# HDSC_HC32M120F6TB register map
Vendor: HDSC Co.,Ltd.; Series: ARMCM0P; File version: 1.0
CPU: CM0P r0p1, little endian, no MPU, no FPU, 4 interrupt priority bits
Registers are 32-bit, read-write, reset 0x0 unless marked. A register's access mark holds for its fields unless they carry their own. Offsets are from the block's base; [hi:lo] are bit positions; {n}, {i} and the like mark numbered series; 'fields as' and 'values as' point back to an identical list.

## PWC
Base 0x40014000
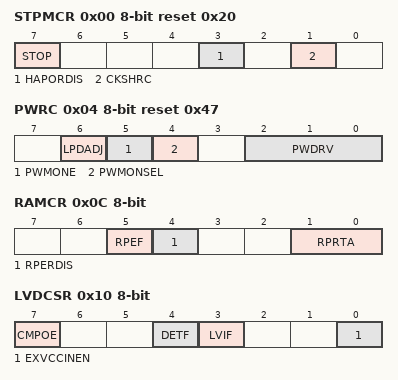
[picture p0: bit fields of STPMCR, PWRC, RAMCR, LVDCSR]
0x00 STPMCR 8-bit reset 0x20
  [7] STOP, [3] HAPORDIS, [1] CKSHRC
0x04 PWRC 8-bit reset 0x47
  [6] LPDADJ, [5] PWMONE, [4] PWMONSEL, [2:0] PWDRV
0x0C RAMCR 8-bit
  [5] RPEF, [4] RPERDIS, [1:0] RPRTA
0x10 LVDCSR 8-bit
  [7] CMPOE, [4] DETF, [3] LVIF ro, [0] EXVCCINEN
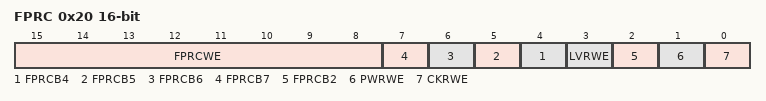
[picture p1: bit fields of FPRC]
0x20 FPRC 16-bit
  [15:8] FPRCWE wo, [n] FPRCB{n} (n=4..7), [3] LVRWE, [2] FPRCB2, [1] PWRWE, [0] CKRWE
0x40 DBGC 8-bit
  [0] DBGEN

## RMU
Base 0x40014100
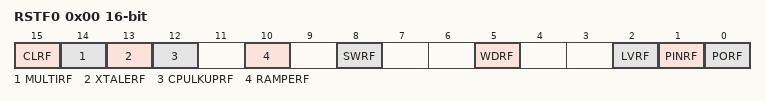
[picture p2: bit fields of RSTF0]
0x00 RSTF0 16-bit
  [15] CLRF, [14] MULTIRF, [13] XTALERF, [12] CPULKUPRF, [10] RAMPERF, [8] SWRF, [5] WDRF, [2] LVRF, [1] PINRF, [0] PORF

## SPI
Base 0x40003800
0x00 DR
  [15:0] SPD
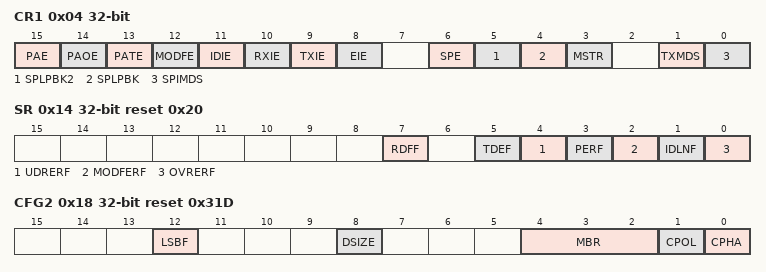
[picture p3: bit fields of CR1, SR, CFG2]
0x04 CR1
  [15] PAE, [14] PAOE, [13] PATE, [12] MODFE, [11] IDIE, [10] RXIE, [9] TXIE, [8] EIE, [6] SPE, [5] SPLPBK2, [4] SPLPBK, [3] MSTR, [1] TXMDS, [0] SPIMDS
0x0C CFG1 reset 0x10
  [8] SS0PV
0x14 SR reset 0x20
  [7] RDFF, [5] TDEF, [4] UDRERF, [3] PERF, [2] MODFERF, [1] IDLNF ro, [0] OVRERF
0x18 CFG2 reset 0x31D (reset mask 0x11F)
  [12] LSBF, [8] DSIZE, [4:2] MBR, [1] CPOL, [0] CPHA

## SWDT
Base 0x4000CC00
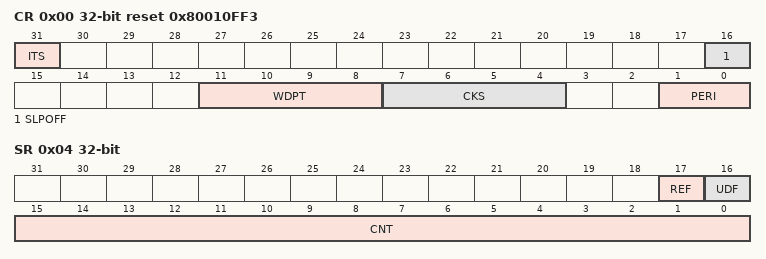
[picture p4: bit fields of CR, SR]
0x00 CR reset 0x80010FF3
  [31] ITS, [16] SLPOFF, [11:8] WDPT, [7:4] CKS, [1:0] PERI
0x04 SR ro
  [17] REF rw, [16] UDF rw, [15:0] CNT
0x08 RR ro
  [15:0] RF

## TMR0
Base 0x40005800
0x00 CNTAR
  [15:0] CNTA
0x08 CMPAR reset 0xFFFF
  [15:0] CMPA
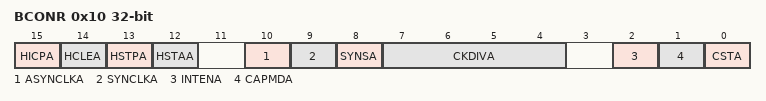
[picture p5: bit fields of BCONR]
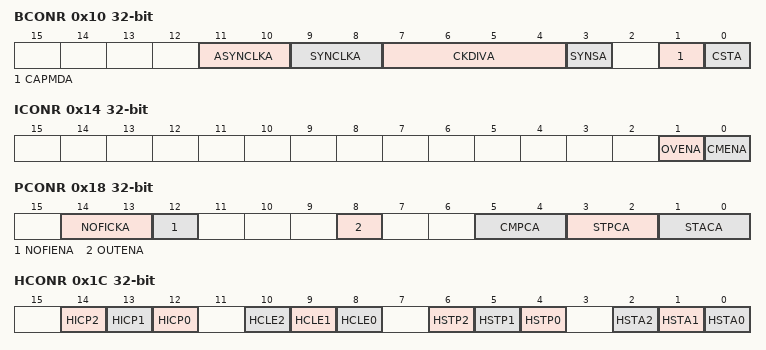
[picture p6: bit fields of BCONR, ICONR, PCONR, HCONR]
0x10 BCONR
  [15] HICPA, [14] HCLEA, [13] HSTPA, [12] HSTAA, [10] ASYNCLKA, [9] SYNCLKA, [8] SYNSA, [7:4] CKDIVA, [2] INTENA, [1] CAPMDA, [0] CSTA
0x14 STFLR
  [0] CMFA

## TMR2
Base 0x40006000
0x00 CNTAR
  [15:0] CNTA
0x08 CMPAR reset 0xFFFF
  [15:0] CMPA
0x10 BCONR
  [11:10] ASYNCLKA, [9:8] SYNCLKA, [7:4] CKDIVA, [3] SYNSA, [1] CAPMDA, [0] CSTA
0x14 ICONR
  [1] OVENA, [0] CMENA
0x18 PCONR
  [14:13] NOFICKA, [12] NOFIENA, [8] OUTENA, [5:4] CMPCA, [3:2] STPCA, [1:0] STACA
0x1C HCONR
  [14] HICP2, [13] HICP1, [12] HICP0, [10] HCLE2, [9] HCLE1, [8] HCLE0, [6] HSTP2, [5] HSTP1, [4] HSTP0, [2] HSTA2, [1] HSTA1, [0] HSTA0
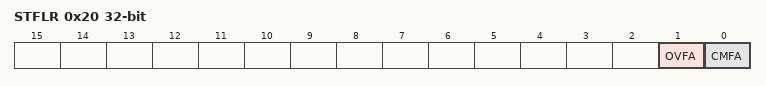
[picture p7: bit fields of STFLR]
0x20 STFLR
  [1] OVFA, [0] CMFA

## TMR4
Base 0x40006800
0x02 OCCRUH 16-bit
0x06 OCCRUL 16-bit
0x0A OCCRVH 16-bit
0x0E OCCRVL 16-bit
0x12 OCCRWH 16-bit
0x16 OCCRWL 16-bit
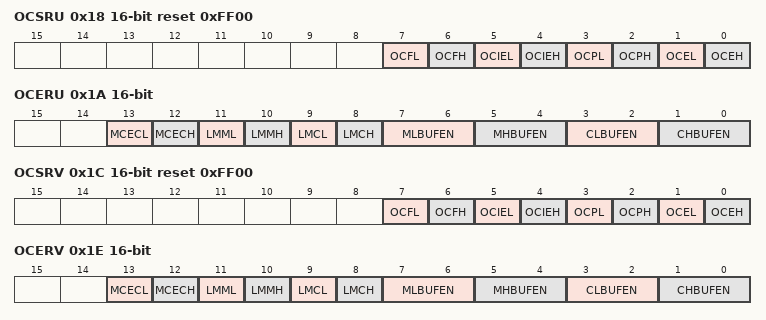
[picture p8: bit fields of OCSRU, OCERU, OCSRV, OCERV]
0x18 OCSRU 16-bit reset 0xFF00
  [7] OCFL, [6] OCFH, [5] OCIEL, [4] OCIEH, [3] OCPL, [2] OCPH, [1] OCEL, [0] OCEH
0x1A OCERU 16-bit
  [13] MCECL, [12] MCECH, [11] LMML, [10] LMMH, [9] LMCL, [8] LMCH, [7:6] MLBUFEN, [5:4] MHBUFEN, [3:2] CLBUFEN, [1:0] CHBUFEN
0x1C OCSRV 16-bit reset 0xFF00
  fields as OCSRU
0x1E OCERV 16-bit
  fields as OCERU
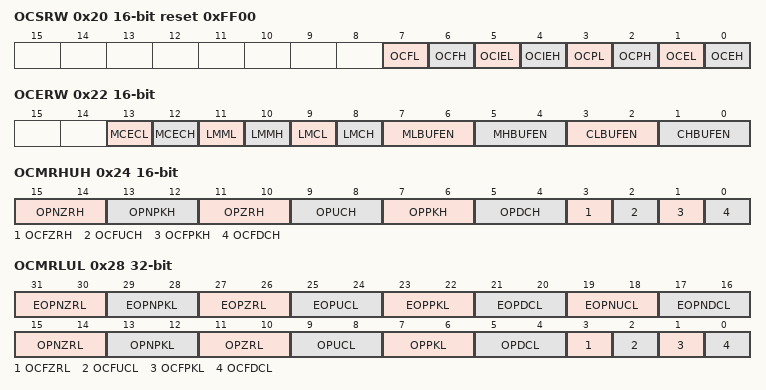
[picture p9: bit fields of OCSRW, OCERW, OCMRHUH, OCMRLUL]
0x20 OCSRW 16-bit reset 0xFF00
  fields as OCSRU
0x22 OCERW 16-bit
  fields as OCERU
0x24 OCMRHUH 16-bit
  [15:14] OPNZRH, [13:12] OPNPKH, [11:10] OPZRH, [9:8] OPUCH, [7:6] OPPKH, [5:4] OPDCH, [3] OCFZRH, [2] OCFUCH, [1] OCFPKH, [0] OCFDCH
0x28 OCMRLUL
  [31:30] EOPNZRL, [29:28] EOPNPKL, [27:26] EOPZRL, [25:24] EOPUCL, [23:22] EOPPKL, [21:20] EOPDCL, [19:18] EOPNUCL, [17:16] EOPNDCL, [15:14] OPNZRL, [13:12] OPNPKL, [11:10] OPZRL, [9:8] OPUCL, [7:6] OPPKL, [5:4] OPDCL, [3] OCFZRL, [2] OCFUCL, [1] OCFPKL, [0] OCFDCL
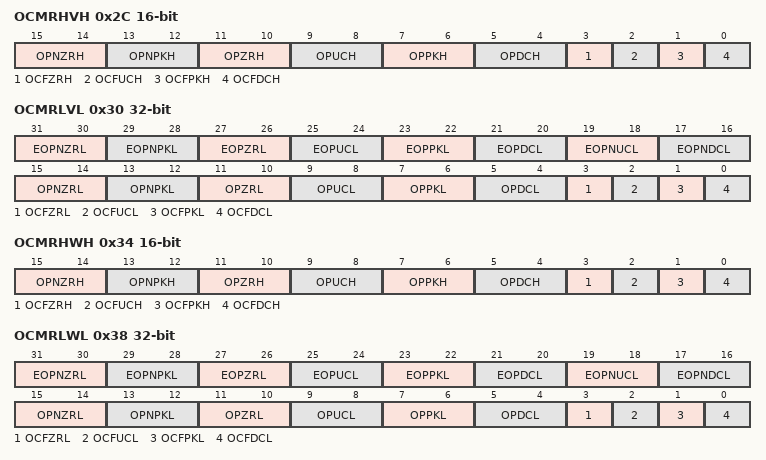
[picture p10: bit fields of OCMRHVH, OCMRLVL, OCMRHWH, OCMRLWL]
0x2C OCMRHVH 16-bit
  fields as OCMRHUH
0x30 OCMRLVL
  fields as OCMRLUL
0x34 OCMRHWH 16-bit
  fields as OCMRHUH
0x38 OCMRLWL
  fields as OCMRLUL
0x42 CPSR 16-bit reset 0xFFFF
0x46 CNTR 16-bit
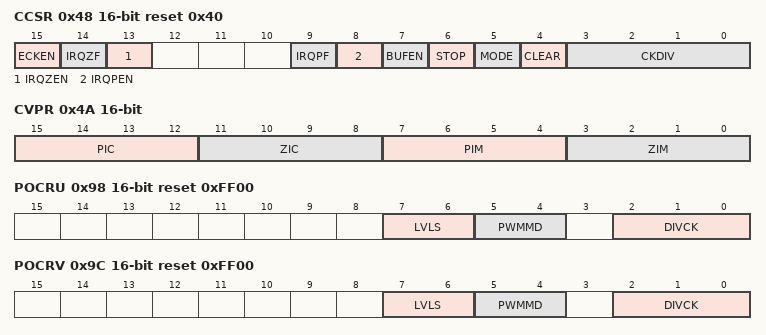
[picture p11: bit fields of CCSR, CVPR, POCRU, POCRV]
0x48 CCSR 16-bit reset 0x40
  [15] ECKEN, [14] IRQZF, [13] IRQZEN, [9] IRQPF, [8] IRQPEN, [7] BUFEN, [6] STOP, [5] MODE, [4] CLEAR, [3:0] CKDIV
0x4A CVPR 16-bit
  [15:12] PIC ro, [11:8] ZIC ro, [7:4] PIM, [3:0] ZIM
0x82 PFSRU 16-bit
0x84 PDARU 16-bit
0x86 PDBRU 16-bit
0x8A PFSRV 16-bit
0x8C PDARV 16-bit
0x8E PDBRV 16-bit
0x92 PFSRW 16-bit
0x94 PDARW 16-bit
0x96 PDBRW 16-bit
0x98 POCRU 16-bit reset 0xFF00
  [7:6] LVLS, [5:4] PWMMD, [2:0] DIVCK
0x9C POCRV 16-bit reset 0xFF00
  [7:6] LVLS, [5:4] PWMMD, [2:0] DIVCK
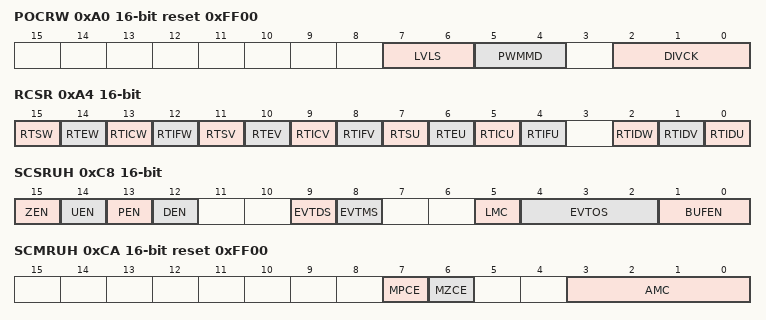
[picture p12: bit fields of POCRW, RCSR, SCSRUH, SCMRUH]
0xA0 POCRW 16-bit reset 0xFF00
  [7:6] LVLS, [5:4] PWMMD, [2:0] DIVCK
0xA4 RCSR 16-bit
  [15] RTSW, [14] RTEW, [13] RTICW, [12] RTIFW ro, [11] RTSV, [10] RTEV, [9] RTICV, [8] RTIFV ro, [7] RTSU, [6] RTEU, [5] RTICU, [4] RTIFU ro, [2] RTIDW, [1] RTIDV, [0] RTIDU
0xB2 SCCRUH 16-bit
0xB6 SCCRUL 16-bit
0xBA SCCRVH 16-bit
0xBE SCCRVL 16-bit
0xC2 SCCRWH 16-bit
0xC6 SCCRWL 16-bit
0xC8 SCSRUH 16-bit
  [15] ZEN, [14] UEN, [13] PEN, [12] DEN, [9] EVTDS, [8] EVTMS, [5] LMC, [4:2] EVTOS, [1:0] BUFEN
0xCA SCMRUH 16-bit reset 0xFF00
  [7] MPCE, [6] MZCE, [3:0] AMC
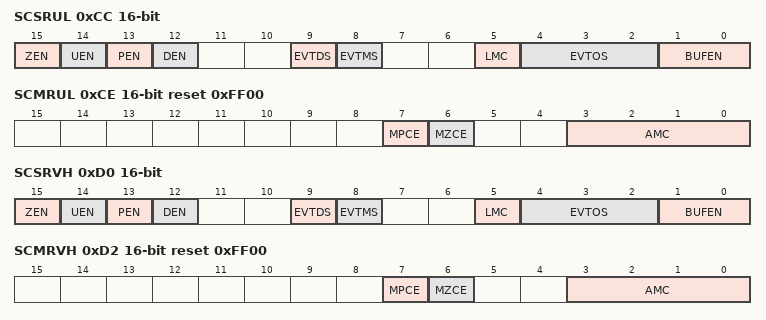
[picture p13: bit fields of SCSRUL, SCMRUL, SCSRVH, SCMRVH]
0xCC SCSRUL 16-bit
  fields as SCSRUH
0xCE SCMRUL 16-bit reset 0xFF00
  [7] MPCE, [6] MZCE, [3:0] AMC
0xD0 SCSRVH 16-bit
  fields as SCSRUH
0xD2 SCMRVH 16-bit reset 0xFF00
  [7] MPCE, [6] MZCE, [3:0] AMC
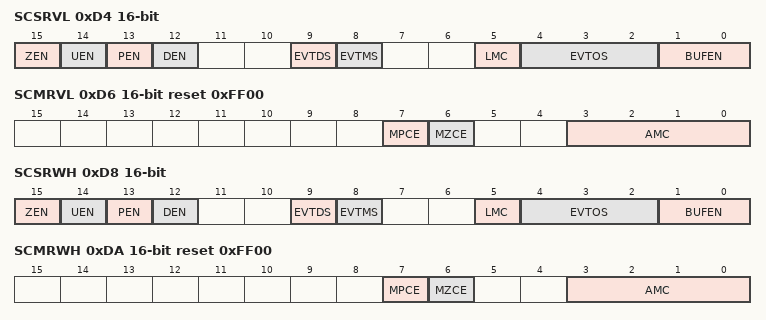
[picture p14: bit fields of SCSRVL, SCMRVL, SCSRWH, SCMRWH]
0xD4 SCSRVL 16-bit
  fields as SCSRUH
0xD6 SCMRVL 16-bit reset 0xFF00
  [7] MPCE, [6] MZCE, [3:0] AMC
0xD8 SCSRWH 16-bit
  fields as SCSRUH
0xDA SCMRWH 16-bit reset 0xFF00
  [7] MPCE, [6] MZCE, [3:0] AMC
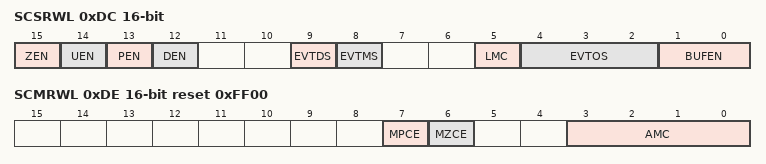
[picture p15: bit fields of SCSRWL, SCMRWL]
0xDC SCSRWL 16-bit
  fields as SCSRUH
0xDE SCMRWL 16-bit reset 0xFF00
  [7] MPCE, [6] MZCE, [3:0] AMC
0x418 ECSR
  [2:0] EMBVAL

## TMRA
Base 0x40007000
0x00 CNTER 16-bit
  [15:0] CNT
0x04 PERAR 16-bit reset 0xFFFF
  [15:0] PER
0x40 CMPAR1 16-bit reset 0xFFFF
  [15:0] CMP
0x44 CMPAR2 16-bit reset 0xFFFF
  [15:0] CMP
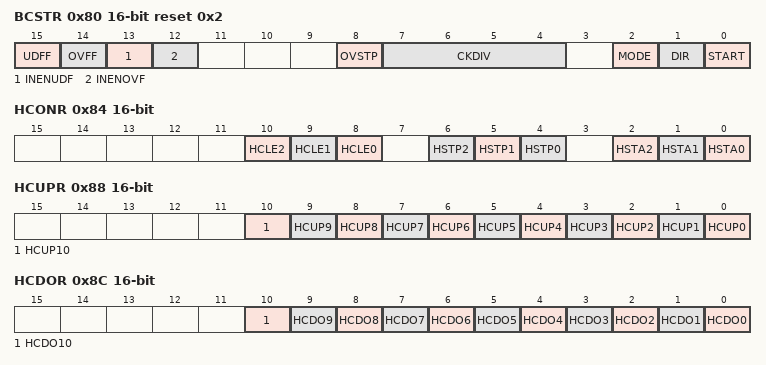
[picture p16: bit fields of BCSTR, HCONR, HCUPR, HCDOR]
0x80 BCSTR 16-bit reset 0x2
  [15] UDFF, [14] OVFF, [13] INENUDF, [12] INENOVF, [8] OVSTP, [7:4] CKDIV, [2] MODE, [1] DIR, [0] START
0x84 HCONR 16-bit
  [10] HCLE2, [9] HCLE1, [8] HCLE0, [6] HSTP2, [5] HSTP1, [4] HSTP0, [2] HSTA2, [1] HSTA1, [0] HSTA0
0x88 HCUPR 16-bit
  [n] HCUP{n} (n=0..10)
0x8C HCDOR 16-bit
  [n] HCDO{n} (n=0..10)
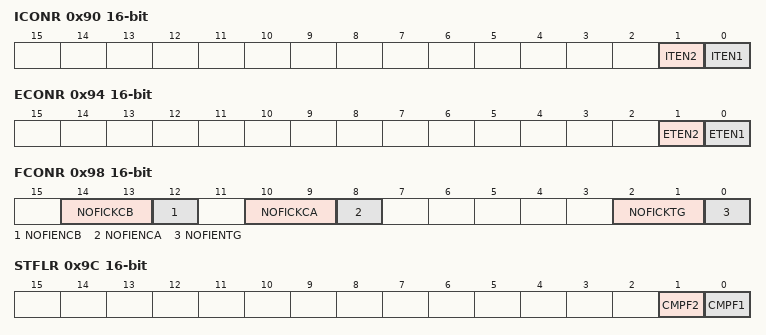
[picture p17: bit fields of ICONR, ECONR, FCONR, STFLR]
0x90 ICONR 16-bit
  [1] ITEN2, [0] ITEN1
0x94 ECONR 16-bit
  [1] ETEN2, [0] ETEN1
0x98 FCONR 16-bit
  [14:13] NOFICKCB, [12] NOFIENCB, [10:9] NOFICKCA, [8] NOFIENCA, [2:1] NOFICKTG, [0] NOFIENTG
0x9C STFLR 16-bit
  [1] CMPF2, [0] CMPF1
0xC0 BCONR 16-bit
  [2] BSE1, [1] BSE0, [0] BEN
0x100 CCONR1 16-bit
  [14:13] NOFICKCP, [12] NOFIENCP, [6] HICP2, [5] HICP1, [4] HICP0, [0] CAPMD
0x104 CCONR2 16-bit
  fields as CCONR1
0x140 PCONR1 16-bit
  [12] OUTEN, [9:8] FORC, [7:6] PERC, [5:4] CMPC, [3:2] STPC, [1:0] STAC
0x144 PCONR2 16-bit
  fields as PCONR1

## TMRB1 — desc TMRB
Base 0x40007800
Same registers: TMRB2 0x40007C00, TMRB3 0x40008000, TMRB4 0x40008400
0x00 CNTER 16-bit
  [15:0] CNT
0x04 PERAR 16-bit reset 0xFFFF
  [15:0] PER
0x40 CMPAR 16-bit reset 0xFFFF
  [15:0] CMP
0x80 BCSTR 16-bit reset 0x2
  [15] UDFF, [14] OVFF, [13] INENUDF, [12] INENOVF, [8] OVSTP, [7:4] CKDIV, [3] SYNST, [2] MODE, [1] DIR, [0] START
0x84 HCONR 16-bit
  [13] HCLE4, [12] HCLE3, [10] HCLE2, [9] HCLE1, [8] HCLE0, [6] HSTP2, [5] HSTP1, [4] HSTP0, [2] HSTA2, [1] HSTA1, [0] HSTA0
0x88 HCUPR 16-bit
  [n] HCUP{n} (n=8..12)
0x8C HCDOR 16-bit
  [n] HCDO{n} (n=8..12)
0x90 ICONR 16-bit
  [0] ITEN1
0x94 ECONR
  [0] ETEN1
0x9C STFLR 16-bit
  [0] CMPF1
0x100 CCONR 16-bit
  [14:13] NOFICKCP, [12] NOFIENCP, [6] HICP2, [5] HICP1, [4] HICP0, [0] CAPMDA
0x140 PCONR 16-bit
  [12] OUTEN, [9:8] FORC, [7:6] PERC, [5:4] CMPC, [3:2] STPC, [1:0] STAC

## USART1 — desc USART
Base 0x40001800
Same registers: USART2 0x40001C00, USART3 0x40002000
0x00 SR ro reset 0xC0
  [16] MPB, [7] TXE, [6] TC, [5] RXNE, [3] ORE, [1] FE, [0] PE
0x04 DR reset 0x1FF
  [24:16] RDR, [9] MPID, [8:0] TDR
0x08 BRR reset 0xFF00
  [15:8] DIV_INTEGER
0x0C CR1 reset 0x80000000
  [31] SBS, [30] NFE, [28] ML, [24] MS, [19] CORE wo, [17] CFE wo, [16] CPE wo, [15] OVER8, [12] M, [10] PCE, [9] PS, [7] TXEIE, [6] TCIE, [5] RIE, [4] SLME, [3] TE, [2] RE
0x10 CR2
  [14] LINEN, [13] STOP, [12:11] CLKC, [0] MPE
0x14 CR3
  [9] CTSE, [3] HDSEL
0x18 PR
  [1:0] PSC
